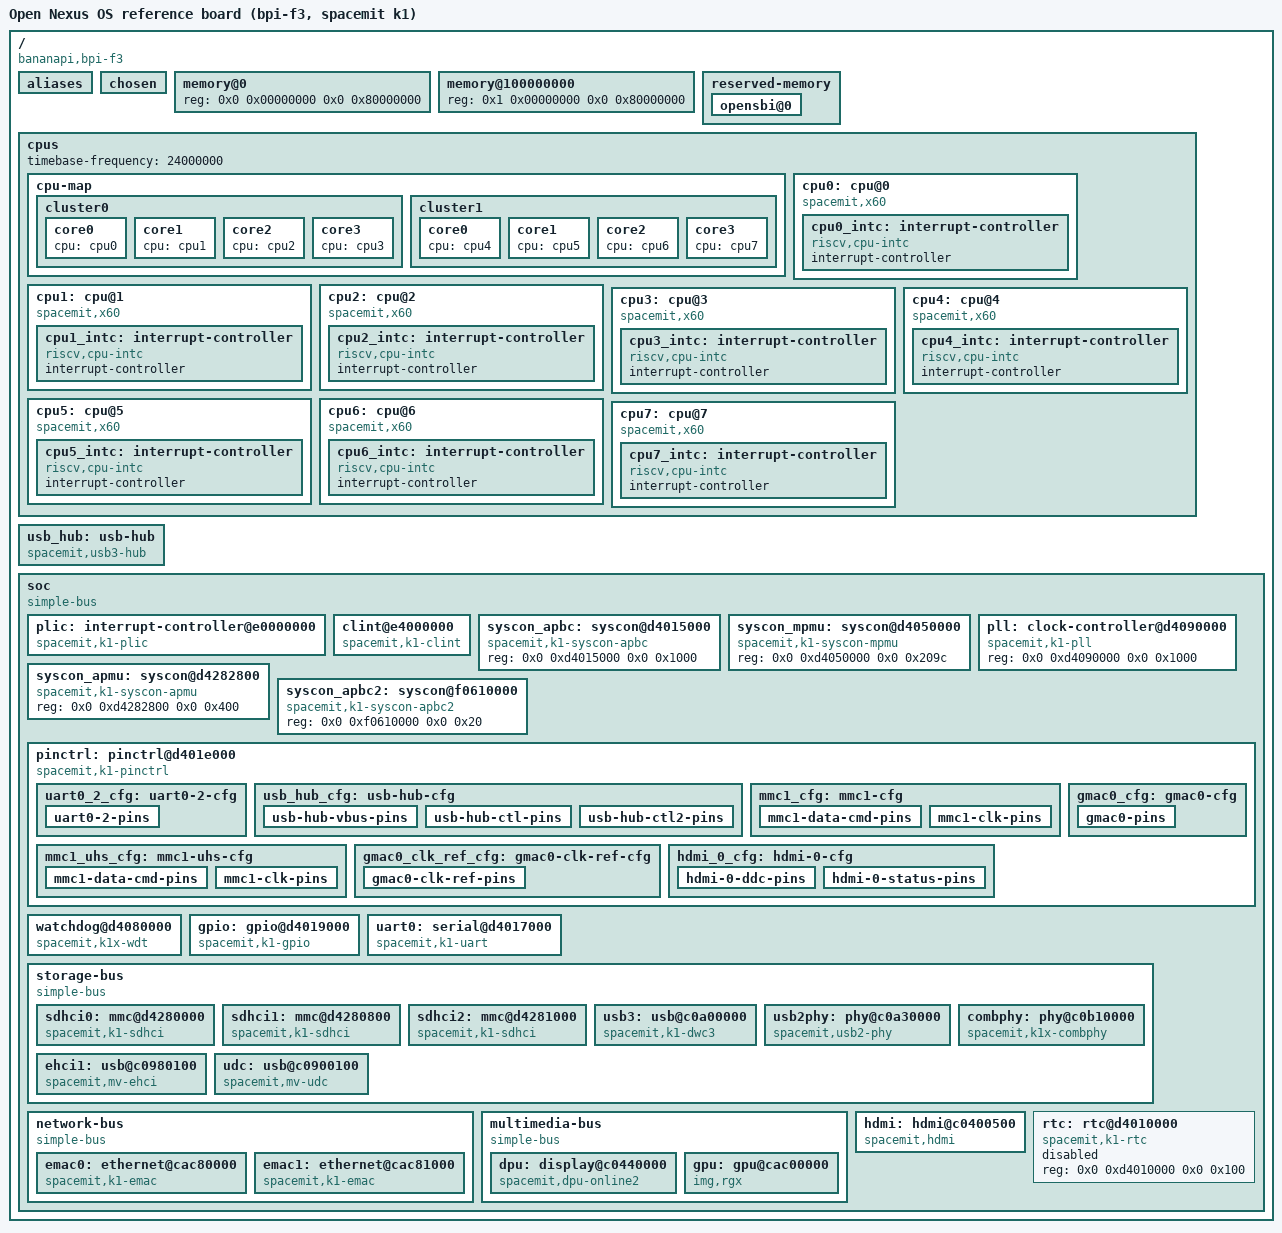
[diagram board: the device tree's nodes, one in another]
// SPDX-License-Identifier: Apache-2.0
// Copyright 2026 Open Nexus OS Contributors
//
// CONTEXT: the reference board's device tree as OUR boot chain hands it to the
// kernel (RFC-0098 C1). Written by hand from two sources and nothing else:
//   * the mainline SoC description (k1.dtsi, "GPL-2.0 OR MIT", used under MIT)
//     for the SoC-level nodes it has (cpus, plic, clint, uart, syscons, sdhci,
//     dwc3, emac, pinctrl);
//   * the facts measured on the desk board on 2026-09-22
//     (docs/board/measurements/2026-09-22-stock-system/README.md) for what
//     mainline does not describe yet (display controller, HDMI encoder, GPU,
//     EHCI, the OTG gadget, the power controller) — compatibles as the hardware
//     reports them, registers and interrupt lines as measured.
// It contains only the nodes Open Nexus OS consumes. Clock, reset, power-domain
// and pad bindings are expressed the standard way (TASK-0245B, RFC-0106): the
// providers carry their `#…-cells`, every consumer names its clocks/resets/
// domains/pads with the ids of config/board/include/dt-bindings (the mainline
// binding header, used under BSD-2-Clause; our own power-domain ids); `socd`
// resolves them through the `nexus-soc` tables, which hold register offsets
// with provenance and never an address.
//
// Compiled by scripts/build-board-dtb.sh (cpp for the headers, `dtc -p 512` for
// nxboot's /chosen headroom) into the FIT (ADR-0066) and, for the host tests of
// `nexus-fdt` and `nexus-soc`, into source/libs/nexus-fdt/tests/goldens/bpi-f3.dtb.

/dts-v1/;

#include <dt-bindings/clock/spacemit,k1-syscon.h>
#include <dt-bindings/power/spacemit,k1-pmu.h>

/* A pad-group entry: the pad number and its mux function (mainline convention). */
#define K1_PADCONF(pin, func) (((pin) << 16) | (func))

/ {
	compatible = "bananapi,bpi-f3", "spacemit,k1";
	model = "Open Nexus OS reference board (bpi-f3, spacemit k1)";
	#address-cells = <2>;
	#size-cells = <2>;

	aliases {
		serial0 = &uart0;
		mmc0 = &sdhci0;
		mmc1 = &sdhci1;
		mmc2 = &sdhci2;
		ethernet0 = &emac0;
		ethernet1 = &emac1;
	};

	chosen {
		stdout-path = "serial0:115200n8";
		// nexus,boot-profile / nexus,boot-slot / nexus,boot-record /
		// nexus,display-mode are written here by nxboot at boot (RFC-0098 C2).
		// The boot LED (TASK-0260B P3): the board's user LED, `sys-led`, GPIO bank 3
		// line 0 (= gpio 96, active high; measured on the stock system 2026-09-28,
		// docs/board/measurements/2026-09-28-dram-retention). nxboot brings the GPIO
		// block up and pulses it once; the kernel pulses its boot milestones on it —
		// the one channel a boot without a serial adapter leaves. The pad's mux
		// register and the value the stock system runs it with, so the loader sets it
		// before the first pulse: GPIO 96 is pad register 0x1e0 (pinctrl debugfs,
		// 2026-10-03: pin index 120, claimed by GPIO 96 `sys-led`, word 0xb041 — the
		// stock tree's GPIO mux value for that pad). Corrected 2026-10-03: this read
		// 0xd401e180 = 0x440, pinctrl-single's pin INDEX 96, an unclaimed pad.
		nexus,boot-led = <&gpio 3 0 0>;
		nexus,boot-led-pad = <0xd401e1e0 0xb041>;
	};

	// Measured: two banks, a 2 GiB hole between them (4 GiB board).
	memory@0 {
		device_type = "memory";
		reg = <0x0 0x00000000 0x0 0x80000000>;
	};

	memory@100000000 {
		device_type = "memory";
		reg = <0x1 0x00000000 0x0 0x80000000>;
	};

	reserved-memory {
		#address-cells = <2>;
		#size-cells = <2>;
		ranges;

		// OpenSBI (fw_dynamic, loaded at 0 by the SPL). Measured: the stock
		// system keeps 0..0x80000 reserved.
		opensbi@0 {
			reg = <0x0 0x00000000 0x0 0x00080000>;
			no-map;
		};
	};

	cpus {
		#address-cells = <1>;
		#size-cells = <0>;
		timebase-frequency = <24000000>;

		cpu-map {
			cluster0 {
				core0 { cpu = <&cpu0>; };
				core1 { cpu = <&cpu1>; };
				core2 { cpu = <&cpu2>; };
				core3 { cpu = <&cpu3>; };
			};
			cluster1 {
				core0 { cpu = <&cpu4>; };
				core1 { cpu = <&cpu5>; };
				core2 { cpu = <&cpu6>; };
				core3 { cpu = <&cpu7>; };
			};
		};

		cpu0: cpu@0 {
			compatible = "spacemit,x60", "riscv";
			device_type = "cpu";
			reg = <0>;
			riscv,isa-base = "rv64i";
			riscv,isa-extensions = "i", "m", "a", "f", "d", "c", "v", "zicbom", "zicboz", "zicntr", "zicond", "zicsr", "zifencei", "zihintpause", "zihpm", "zba", "zbb", "zbc", "zbs", "sscofpmf", "sstc", "svinval", "svnapot", "svpbmt";
			riscv,cbom-block-size = <64>;
			riscv,cboz-block-size = <64>;
			mmu-type = "riscv,sv39";
			status = "okay";
			cpu0_intc: interrupt-controller {
				compatible = "riscv,cpu-intc";
				interrupt-controller;
				#interrupt-cells = <1>;
			};
		};

		cpu1: cpu@1 {
			compatible = "spacemit,x60", "riscv";
			device_type = "cpu";
			reg = <1>;
			riscv,isa-base = "rv64i";
			riscv,isa-extensions = "i", "m", "a", "f", "d", "c", "v", "zicbom", "zicboz", "zicntr", "zicond", "zicsr", "zifencei", "zihintpause", "zihpm", "zba", "zbb", "zbc", "zbs", "sscofpmf", "sstc", "svinval", "svnapot", "svpbmt";
			riscv,cbom-block-size = <64>;
			riscv,cboz-block-size = <64>;
			mmu-type = "riscv,sv39";
			status = "okay";
			cpu1_intc: interrupt-controller {
				compatible = "riscv,cpu-intc";
				interrupt-controller;
				#interrupt-cells = <1>;
			};
		};

		cpu2: cpu@2 {
			compatible = "spacemit,x60", "riscv";
			device_type = "cpu";
			reg = <2>;
			riscv,isa-base = "rv64i";
			riscv,isa-extensions = "i", "m", "a", "f", "d", "c", "v", "zicbom", "zicboz", "zicntr", "zicond", "zicsr", "zifencei", "zihintpause", "zihpm", "zba", "zbb", "zbc", "zbs", "sscofpmf", "sstc", "svinval", "svnapot", "svpbmt";
			riscv,cbom-block-size = <64>;
			riscv,cboz-block-size = <64>;
			mmu-type = "riscv,sv39";
			status = "okay";
			cpu2_intc: interrupt-controller {
				compatible = "riscv,cpu-intc";
				interrupt-controller;
				#interrupt-cells = <1>;
			};
		};

		cpu3: cpu@3 {
			compatible = "spacemit,x60", "riscv";
			device_type = "cpu";
			reg = <3>;
			riscv,isa-base = "rv64i";
			riscv,isa-extensions = "i", "m", "a", "f", "d", "c", "v", "zicbom", "zicboz", "zicntr", "zicond", "zicsr", "zifencei", "zihintpause", "zihpm", "zba", "zbb", "zbc", "zbs", "sscofpmf", "sstc", "svinval", "svnapot", "svpbmt";
			riscv,cbom-block-size = <64>;
			riscv,cboz-block-size = <64>;
			mmu-type = "riscv,sv39";
			status = "okay";
			cpu3_intc: interrupt-controller {
				compatible = "riscv,cpu-intc";
				interrupt-controller;
				#interrupt-cells = <1>;
			};
		};

		cpu4: cpu@4 {
			compatible = "spacemit,x60", "riscv";
			device_type = "cpu";
			reg = <4>;
			riscv,isa-base = "rv64i";
			riscv,isa-extensions = "i", "m", "a", "f", "d", "c", "v", "zicbom", "zicboz", "zicntr", "zicond", "zicsr", "zifencei", "zihintpause", "zihpm", "zba", "zbb", "zbc", "zbs", "sscofpmf", "sstc", "svinval", "svnapot", "svpbmt";
			riscv,cbom-block-size = <64>;
			riscv,cboz-block-size = <64>;
			mmu-type = "riscv,sv39";
			status = "okay";
			cpu4_intc: interrupt-controller {
				compatible = "riscv,cpu-intc";
				interrupt-controller;
				#interrupt-cells = <1>;
			};
		};

		cpu5: cpu@5 {
			compatible = "spacemit,x60", "riscv";
			device_type = "cpu";
			reg = <5>;
			riscv,isa-base = "rv64i";
			riscv,isa-extensions = "i", "m", "a", "f", "d", "c", "v", "zicbom", "zicboz", "zicntr", "zicond", "zicsr", "zifencei", "zihintpause", "zihpm", "zba", "zbb", "zbc", "zbs", "sscofpmf", "sstc", "svinval", "svnapot", "svpbmt";
			riscv,cbom-block-size = <64>;
			riscv,cboz-block-size = <64>;
			mmu-type = "riscv,sv39";
			status = "okay";
			cpu5_intc: interrupt-controller {
				compatible = "riscv,cpu-intc";
				interrupt-controller;
				#interrupt-cells = <1>;
			};
		};

		cpu6: cpu@6 {
			compatible = "spacemit,x60", "riscv";
			device_type = "cpu";
			reg = <6>;
			riscv,isa-base = "rv64i";
			riscv,isa-extensions = "i", "m", "a", "f", "d", "c", "v", "zicbom", "zicboz", "zicntr", "zicond", "zicsr", "zifencei", "zihintpause", "zihpm", "zba", "zbb", "zbc", "zbs", "sscofpmf", "sstc", "svinval", "svnapot", "svpbmt";
			riscv,cbom-block-size = <64>;
			riscv,cboz-block-size = <64>;
			mmu-type = "riscv,sv39";
			status = "okay";
			cpu6_intc: interrupt-controller {
				compatible = "riscv,cpu-intc";
				interrupt-controller;
				#interrupt-cells = <1>;
			};
		};

		cpu7: cpu@7 {
			compatible = "spacemit,x60", "riscv";
			device_type = "cpu";
			reg = <7>;
			riscv,isa-base = "rv64i";
			riscv,isa-extensions = "i", "m", "a", "f", "d", "c", "v", "zicbom", "zicboz", "zicntr", "zicond", "zicsr", "zifencei", "zihintpause", "zihpm", "zba", "zbb", "zbc", "zbs", "sscofpmf", "sstc", "svinval", "svnapot", "svpbmt";
			riscv,cbom-block-size = <64>;
			riscv,cboz-block-size = <64>;
			mmu-type = "riscv,sv39";
			status = "okay";
			cpu7_intc: interrupt-controller {
				compatible = "riscv,cpu-intc";
				interrupt-controller;
				#interrupt-cells = <1>;
			};
		};
	};

	// The on-board USB hub (TASK-0328 U3, the stock `usb3hub@0` binding's shape; measured
	// 2026-10-04: GPIO 97 = VBUS, 123 and 124 = the hub's lines, all outputs driven high;
	// pads 97 mux 1 `0xa041`, 123 `0xa040`, 124 `0xd040`; the stock driver raises VBUS
	// 200 ms after the hub's lines). Bank 3 line n = GPIO 96 + n. socd drives the lines
	// (RFC-0106, amended): hub lines, the settle, then VBUS — before xhcid scans the port.
	// Not a bus device (no registers of its own), so it lives at the root like a regulator.
	usb_hub: usb-hub {
		compatible = "spacemit,usb3-hub";
		pinctrl-names = "default";
		pinctrl-0 = <&usb_hub_cfg>;
		hub-gpios = <&gpio 3 27 0>, <&gpio 3 28 0>;
		vbus-gpios = <&gpio 3 1 0>;
		vbus-delay-ms = <200>;
	};

	soc {
		compatible = "simple-bus";
		#address-cells = <2>;
		#size-cells = <2>;
		ranges;
		interrupt-parent = <&plic>;
		/* Measured R4 (docs/board/measurements/2026-09-22-stock-system): the
		 * masters do not snoop the CPU caches — the stock kernel bounces through
		 * swiotlb; the mainline K1 tree marks the bus the same way (RFC-0098 C4). */
		dma-noncoherent;

		plic: interrupt-controller@e0000000 {
			compatible = "spacemit,k1-plic", "sifive,plic-1.0.0", "riscv,plic0";
			reg = <0x0 0xe0000000 0x0 0x4000000>;
			interrupt-controller;
			#interrupt-cells = <1>;
			#address-cells = <0>;
			riscv,ndev = <159>;
			interrupts-extended = <&cpu0_intc 11>, <&cpu0_intc 9>,
					      <&cpu1_intc 11>, <&cpu1_intc 9>,
					      <&cpu2_intc 11>, <&cpu2_intc 9>,
					      <&cpu3_intc 11>, <&cpu3_intc 9>,
					      <&cpu4_intc 11>, <&cpu4_intc 9>,
					      <&cpu5_intc 11>, <&cpu5_intc 9>,
					      <&cpu6_intc 11>, <&cpu6_intc 9>,
					      <&cpu7_intc 11>, <&cpu7_intc 9>;
		};

		// M-mode only: S-mode never maps it. The SPL hands this very tree to OpenSBI,
		// whose ACLINT drivers serve exactly the harts named here (IPI: MSIP 3, timer:
		// MTIP 7). Without the list its timer serves no hart and it stops before the
		// next stage (OpenSBI v1.3: fdt_parse_aclint_node, aclint_mtimer_warm_init →
		// "timer init failed"; TASK-0260B, the first board attempt).
		clint@e4000000 {
			compatible = "spacemit,k1-clint", "sifive,clint0";
			reg = <0x0 0xe4000000 0x0 0x10000>;
			interrupts-extended = <&cpu0_intc 3>, <&cpu0_intc 7>,
					      <&cpu1_intc 3>, <&cpu1_intc 7>,
					      <&cpu2_intc 3>, <&cpu2_intc 7>,
					      <&cpu3_intc 3>, <&cpu3_intc 7>,
					      <&cpu4_intc 3>, <&cpu4_intc 7>,
					      <&cpu5_intc 3>, <&cpu5_intc 7>,
					      <&cpu6_intc 3>, <&cpu6_intc 7>,
					      <&cpu7_intc 3>, <&cpu7_intc 7>;
		};

		// The clock/reset/power syscon windows (mainline names); the providers
		// `socd` owns (RFC-0106). Ids per dt-bindings/clock/spacemit,k1-syscon.h.
		syscon_apbc: syscon@d4015000 {
			compatible = "spacemit,k1-syscon-apbc";
			reg = <0x0 0xd4015000 0x0 0x1000>;
			#clock-cells = <1>;
			#reset-cells = <1>;
		};
		syscon_mpmu: syscon@d4050000 {
			compatible = "spacemit,k1-syscon-mpmu";
			reg = <0x0 0xd4050000 0x0 0x209c>;
			#clock-cells = <1>;
			// A consumer's glue words in the MPMU (`<&syscon_mpmu offset mask value>`,
			// TASK-0328 U3: the USB PHYs' clock control word at 0x14).
			#nexus,glue-cells = <3>;
			#reset-cells = <1>;
			#power-domain-cells = <1>;
		};
		pll: clock-controller@d4090000 {
			compatible = "spacemit,k1-pll";
			reg = <0x0 0xd4090000 0x0 0x1000>;
			#clock-cells = <1>;
		};
		syscon_apmu: syscon@d4282800 {
			compatible = "spacemit,k1-syscon-apmu";
			reg = <0x0 0xd4282800 0x0 0x400>;
			#clock-cells = <1>;
			#reset-cells = <1>;
			// A consumer's glue words (`nexus,glue-words = <&syscon_apmu offset mask value>`):
			// a vendor driver's one-word controller glue, its `mask` bits set by socd, the
			// rest (status bits) left alone (TASK-0328 U3: the USB host's word at 0x3c8).
			#nexus,glue-cells = <3>;
			#power-domain-cells = <1>;
		};
		syscon_apbc2: syscon@f0610000 {
			compatible = "spacemit,k1-syscon-apbc2";
			reg = <0x0 0xf0610000 0x0 0x20>;
			#reset-cells = <1>;
		};

		pinctrl: pinctrl@d401e000 {
			compatible = "spacemit,k1-pinctrl";
			reg = <0x0 0xd401e000 0x0 0x1000>;
			clocks = <&syscon_apbc CLK_AIB>, <&syscon_apbc CLK_AIB_BUS>;
			clock-names = "func", "bus";
			resets = <&syscon_apbc RESET_AIB>;

			// Pad groups (mainline k1-pinctrl.dtsi, GPL-2.0 OR MIT, used under
			// MIT): only the ones our consumers reference.
			uart0_2_cfg: uart0-2-cfg {
				uart0-2-pins {
					pinmux = <K1_PADCONF(68, 2)>,	/* uart0_txd */
						 <K1_PADCONF(69, 2)>;	/* uart0_rxd */
					bias-pull-up = <0>;
					drive-strength = <32>;
				};
			};

			// The on-board USB hub's lines as GPIOs (TASK-0328 U3; the owned fields of
			// the stock words: 97 `0xa041` = function 1 pull-down, 123 `0xa040` = function 0
			// pull-down, 124 `0xd040` = function 0 pull-up).
			usb_hub_cfg: usb-hub-cfg {
				usb-hub-vbus-pins {
					pinmux = <K1_PADCONF(97, 1)>;	/* gpio 97: VBUS */
					bias-pull-down = <0>;
				};
				usb-hub-ctl-pins {
					pinmux = <K1_PADCONF(123, 0)>;	/* gpio 123 */
					bias-pull-down = <0>;
				};
				usb-hub-ctl2-pins {
					pinmux = <K1_PADCONF(124, 0)>;	/* gpio 124 */
					bias-pull-up = <0>;
				};
			};

			mmc1_cfg: mmc1-cfg {
				mmc1-data-cmd-pins {
					pinmux = <K1_PADCONF(104, 0)>,	/* mmc1_d3 */
						 <K1_PADCONF(105, 0)>,	/* mmc1_d2 */
						 <K1_PADCONF(106, 0)>,	/* mmc1_d1 */
						 <K1_PADCONF(107, 0)>,	/* mmc1_d0 */
						 <K1_PADCONF(108, 0)>;	/* mmc1_cmd */
					bias-pull-up = <1>;
					drive-strength = <19>;
					power-source = <3300>;
				};
				mmc1-clk-pins {
					pinmux = <K1_PADCONF(109, 0)>;	/* mmc1_clk */
					bias-pull-down = <1>;
					drive-strength = <19>;
					power-source = <3300>;
				};
			};

			mmc1_uhs_cfg: mmc1-uhs-cfg {
				mmc1-data-cmd-pins {
					pinmux = <K1_PADCONF(104, 0)>,
						 <K1_PADCONF(105, 0)>,
						 <K1_PADCONF(106, 0)>,
						 <K1_PADCONF(107, 0)>,
						 <K1_PADCONF(108, 0)>;
					bias-pull-up = <1>;
					drive-strength = <42>;
					power-source = <1800>;
				};
				mmc1-clk-pins {
					pinmux = <K1_PADCONF(109, 0)>;
					bias-pull-down = <1>;
					drive-strength = <42>;
					power-source = <1800>;
				};
			};

			gmac0_cfg: gmac0-cfg {
				gmac0-pins {
					pinmux = <K1_PADCONF(0, 1)>,	/* gmac0_rxdv */
						 <K1_PADCONF(1, 1)>,	/* gmac0_rx_d0 */
						 <K1_PADCONF(2, 1)>,	/* gmac0_rx_d1 */
						 <K1_PADCONF(3, 1)>,	/* gmac0_rx_clk */
						 <K1_PADCONF(4, 1)>,	/* gmac0_rx_d2 */
						 <K1_PADCONF(5, 1)>,	/* gmac0_rx_d3 */
						 <K1_PADCONF(6, 1)>,	/* gmac0_tx_d0 */
						 <K1_PADCONF(7, 1)>,	/* gmac0_tx_d1 */
						 <K1_PADCONF(8, 1)>,	/* gmac0_tx */
						 <K1_PADCONF(9, 1)>,	/* gmac0_tx_d2 */
						 <K1_PADCONF(10, 1)>,	/* gmac0_tx_d3 */
						 <K1_PADCONF(11, 1)>,	/* gmac0_tx_en */
						 <K1_PADCONF(12, 1)>;	/* gmac0_mdc */
					bias-pull-up = <0>;
					drive-strength = <21>;
				};
			};
			gmac0_clk_ref_cfg: gmac0-clk-ref-cfg {
				gmac0-clk-ref-pins {
					pinmux = <K1_PADCONF(45, 1)>;	/* gmac0_clk_ref */
					bias-pull-up = <0>;
					drive-strength = <21>;
				};
			};

			// The HDMI encoder's four pads (the stock system's `hdmi_0_grp`, read live
			// 2026-10-03, docs/board/measurements/2026-10-03-first-light/: function 1;
			// words 0xd041 on the first two, pulled up — the DDC pair — and 0xb041 on the
			// other two, pulled down). Without them the encoder sees no hot-plug.
			hdmi_0_cfg: hdmi-0-cfg {
				hdmi-0-ddc-pins {
					pinmux = <K1_PADCONF(86, 1)>,
						 <K1_PADCONF(87, 1)>;
					bias-pull-up;
				};
				hdmi-0-status-pins {
					pinmux = <K1_PADCONF(88, 1)>,
						 <K1_PADCONF(89, 1)>;
					bias-pull-down;
				};
			};
		};

		// The SoC watchdog (the vendor U-Boot's tree, `k1-x.dtsi`: the register window and
		// the reset-enable word at 0xd4051020). Named so nxboot can STOP it: the vendor
		// chain's U-Boot starts, feeds and stops it before Linux; ours never runs U-Boot
		// (TASK-0260B P3 — the kernel died mid-line, seconds in, until this). Nothing
		// else consumes it; its clock is the one it is already running on.
		watchdog@d4080000 {
			compatible = "spacemit,k1x-wdt";
			reg = <0x0 0xd4080000 0x0 0x1000>,
			      <0x0 0xd4051020 0x0 0x4>;
		};

		// The GPIO block (mainline shape; reg as the stock system maps it — the driver's
		// bank 3 lies at +0x100). Consumed for the boot LED only (TASK-0260B P3).
		gpio: gpio@d4019000 {
			compatible = "spacemit,k1-gpio";
			reg = <0x0 0xd4019000 0x0 0x800>;
			clocks = <&syscon_apbc CLK_GPIO>, <&syscon_apbc CLK_GPIO_BUS>;
			clock-names = "core", "bus";
			gpio-controller;
			#gpio-cells = <3>;
		};

		// The debug console: 16550-class registers at a 4-byte stride. `spacemit,pxa-uart`
		// is the name the pinned OpenSBI's console driver matches (its binary's match
		// strings, TASK-0260B), so the firmware prints on it too.
		uart0: serial@d4017000 {
			compatible = "spacemit,k1-uart", "spacemit,pxa-uart", "intel,xscale-uart";
			reg = <0x0 0xd4017000 0x0 0x100>;
			reg-shift = <2>;
			reg-io-width = <4>;
			interrupts = <42>;
			clocks = <&syscon_apbc CLK_UART0>, <&syscon_apbc CLK_UART0_BUS>;
			clock-names = "core", "bus";
			resets = <&syscon_apbc RESET_UART0>;
			pinctrl-names = "default";
			pinctrl-0 = <&uart0_2_cfg>;
			status = "okay";
		};

		// DMA reach (RFC-0098 C4), measured 2026-09-24 (docs/board/measurements/
		// 2026-09-24-emmc-sdhci): the stock tree's `dram_range@0`, mainline's `storage-bus`.
		// The storage masters reach ONLY the first 2 GiB, identity; bank 1 is out of reach.
		storage-bus {
			compatible = "simple-bus";
			ranges;
			#address-cells = <2>;
			#size-cells = <2>;
			dma-ranges = <0x0 0x00000000 0x0 0x00000000 0x0 0x80000000>;

			// What each SD host may carry, the standard way (`no-mmc`/`no-sd`/`no-sdio`), as the
			// stock system's live tree marks them (measured 2026-09-26, docs/board/measurements/
			// 2026-09-24-emmc-sdhci/live-tree-sdh.txt): the loader's boot-disk rule and the block
			// owner treat only a host without `no-mmc` as one that may hold an eMMC.

			// The microSD slot.
			sdhci0: mmc@d4280000 {
				compatible = "spacemit,k1-sdhci";
				reg = <0x0 0xd4280000 0x0 0x200>;
				interrupts = <99>;
				clocks = <&syscon_apmu CLK_SDH_AXI>, <&syscon_apmu CLK_SDH0>;
				clock-names = "core", "io";
				resets = <&syscon_apmu RESET_SDH_AXI>, <&syscon_apmu RESET_SDH0>;
				reset-names = "axi", "sdh";
				power-domains = <&syscon_apmu K1_PD_BUS>;
				pinctrl-names = "default", "uhs";
				pinctrl-0 = <&mmc1_cfg>;
				pinctrl-1 = <&mmc1_uhs_cfg>;
				bus-width = <4>;
				no-mmc;
				no-sdio;
				status = "okay";
			};

			// The SDIO WiFi function.
			sdhci1: mmc@d4280800 {
				compatible = "spacemit,k1-sdhci";
				reg = <0x0 0xd4280800 0x0 0x200>;
				interrupts = <100>;
				clocks = <&syscon_apmu CLK_SDH_AXI>, <&syscon_apmu CLK_SDH1>;
				clock-names = "core", "io";
				resets = <&syscon_apmu RESET_SDH_AXI>, <&syscon_apmu RESET_SDH1>;
				reset-names = "axi", "sdh";
				power-domains = <&syscon_apmu K1_PD_BUS>;
				bus-width = <4>;
				non-removable;
				no-mmc;
				no-sd;
				status = "okay";
			};

			// The system disk (eMMC, 8-bit, HS400 with enhanced strobe at 1.8 V).
			sdhci2: mmc@d4281000 {
				compatible = "spacemit,k1-sdhci";
				reg = <0x0 0xd4281000 0x0 0x200>;
				interrupts = <101>;
				clocks = <&syscon_apmu CLK_SDH_AXI>, <&syscon_apmu CLK_SDH2>;
				clock-names = "core", "io";
				resets = <&syscon_apmu RESET_SDH_AXI>, <&syscon_apmu RESET_SDH2>;
				reset-names = "axi", "sdh";
				power-domains = <&syscon_apmu K1_PD_BUS>;
				bus-width = <8>;
				non-removable;
				no-sd;
				no-sdio;
				mmc-hs400-1_8v;
				mmc-hs400-enhanced-strobe;
				status = "okay";
			};

			// USB: the DWC3 host (xHCI), the EHCI host, the OTG gadget.
			// TASK-0328 U3 (RFC-0099 §6): the host's glue as measured on the stock system
			// (docs/board/measurements/2026-10-04-usb-topology/): the APMU glue word at
			// 0x3c8 (the stock glue node's own register, `0xd4282bc8 = 0x0b008000`), the
			// USB 2.0 PHY it drives the USB-A ports through (the SuperSpeed lane is left
			// alone in v1), and the on-board hub on its USB 2.0 root port (`usb_hub`).
			usb3: usb@c0a00000 {
				compatible = "spacemit,k1-dwc3", "snps,dwc3";
				reg = <0x0 0xc0a00000 0x0 0x10000>;
				interrupts = <125>;
				// The USB AXI clock and reset too (bits 1 and 0 of the APMU USB word): the
				// stock system runs the word as 0x0f33; cycle 6 of U3 had 0xf00 and an xHCI
				// that never left its reset.
				clocks = <&syscon_apmu CLK_USB30>, <&syscon_apmu CLK_USB_AXI>;
				clock-names = "usbdrd30", "axi";
				resets = <&syscon_apmu RESET_USB30_AHB>, <&syscon_apmu RESET_USB30_VCC>,
					 <&syscon_apmu RESET_USB30_PHY>, <&syscon_apmu RESET_USB_AXI>;
				reset-names = "ahb", "vcc", "phy", "axi";
				power-domains = <&syscon_apmu K1_PD_BUS>;
				// The stock word is 0x0b008000; its bits 24..25 are status (cycle 1,
				// 2026-10-05: written, they read back clear — docs/board/measurements/
				// 2026-10-05-usb-cycle1/), so only bit 15 is the glue.
				nexus,glue-words = <&syscon_apmu 0x3c8 0x00008000 0x00008000>;
				usb-phy = <&usb2phy>;
				dr_mode = "host";
				status = "okay";
			};

			// The USB 2.0 PHY of the DWC3 host (stock `usb2phy@0xc0a30000`): xhcid reads its
			// tuning words and compares them with the stock system's (U3's first cycle).
			usb2phy: phy@c0a30000 {
				compatible = "spacemit,usb2-phy";
				reg = <0x0 0xc0a30000 0x0 0x200>;
				clocks = <&syscon_apmu CLK_USB30>;
				clock-names = "usbdrd30";
				// The MPMU word at 0x14 as the stock system runs it (cycle 8 of U3 measured
				// ours as 0x1fbd0600 with both USB PHYs dead; the stock desktop 0x007d0018):
				// the PHYs' clock control by the look of it — written whole, each bit
				// read back, through socd before xhcid touches the PHY.
				nexus,glue-words = <&syscon_mpmu 0x14 0xffffffff 0x007d0018>;
				#phy-cells = <0>;
				status = "okay";
			};

			// The SuperSpeed (combo) PHY of the host's USB 3.0 root port (stock
			// `phy@c0b10000`, its `puphy` block; the stock `phy_sel` block is the APMU's
			// own words). The xHCI's reset waits on this PHY's PIPE clock (cycles 4-9 of
			// U3: HCRST never completed with the block reading all zeros), so it is
			// brought up, not only measured: the PHY shares PCIe port A's global reset
			// (bit 8 of the APMU's 0x3cc, SET = held — our loader leaves it set, the
			// stock word 0x480 runs it clear) and the port's "hold PHY reset" bit (bit 30
			// of the same word, the vendor PHY driver clears it before calibrating); the
			// lane select at 0x110 (stock 0x8) puts the lane on USB. socd writes them
			// before xhcid runs the PHY's PLL sequence (`ss_phy.rs`).
			combphy: phy@c0b10000 {
				compatible = "spacemit,k1x-combphy";
				reg = <0x0 0xc0b10000 0x0 0x800>;
				resets = <&syscon_apmu RESET_PCIE0_GLOBAL>;
				reset-names = "phy";
				nexus,glue-words = <&syscon_apmu 0x3cc 0x40000000 0x00000000>,
						   <&syscon_apmu 0x110 0x00000008 0x00000008>;
				#phy-cells = <1>;
				status = "okay";
			};

			ehci1: usb@c0980100 {
				compatible = "spacemit,mv-ehci";
				reg = <0x0 0xc0980100 0x0 0x4000>;
				interrupts = <118>;
				clocks = <&syscon_apmu CLK_USB_P1>;
				resets = <&syscon_apmu RESET_USBP1_AXI>;
				power-domains = <&syscon_apmu K1_PD_BUS>;
				status = "okay";
			};

			udc: usb@c0900100 {
				compatible = "spacemit,mv-udc";
				reg = <0x0 0xc0900100 0x0 0x4000>;
				interrupts = <105>;
				clocks = <&syscon_apmu CLK_USB_AXI>;
				resets = <&syscon_apmu RESET_USB_AXI>;
				power-domains = <&syscon_apmu K1_PD_BUS>;
				status = "okay";
			};
		};

		// The GMACs (stock `dram_range@5`, mainline `network-bus`): the first 2 GiB identity, and
		// bus 0x8000_0000.. reaches CPU 0x1_0000_0000.. (2 GiB) — a translated window.
		network-bus {
			compatible = "simple-bus";
			ranges;
			#address-cells = <2>;
			#size-cells = <2>;
			dma-ranges = <0x0 0x00000000 0x0 0x00000000 0x0 0x80000000>,
				     <0x0 0x80000000 0x1 0x00000000 0x0 0x80000000>;

			emac0: ethernet@cac80000 {
				compatible = "spacemit,k1-emac";
				reg = <0x0 0xcac80000 0x0 0x420>;
				interrupts = <131>;
				clocks = <&syscon_apmu CLK_EMAC0_BUS>, <&syscon_apmu CLK_EMAC0_PTP>;
				clock-names = "bus", "ptp";
				resets = <&syscon_apmu RESET_EMAC0>;
				power-domains = <&syscon_apmu K1_PD_BUS>;
				pinctrl-names = "default";
				pinctrl-0 = <&gmac0_cfg>, <&gmac0_clk_ref_cfg>;
				status = "okay";
			};

			emac1: ethernet@cac81000 {
				compatible = "spacemit,k1-emac";
				reg = <0x0 0xcac81000 0x0 0x420>;
				interrupts = <133>;
				clocks = <&syscon_apmu CLK_EMAC1_BUS>, <&syscon_apmu CLK_EMAC1_PTP>;
				clock-names = "bus", "ptp";
				resets = <&syscon_apmu RESET_EMAC1>;
				power-domains = <&syscon_apmu K1_PD_BUS>;
				status = "okay";
			};
		};

		// The display controller and the GPU (stock `dram_range@1`; mainline has the bus, not yet
		// these nodes): the first 2 GiB identity, and bus 0x8000_0000.. reaches CPU
		// 0x1_0000_0000.. (14 GiB).
		multimedia-bus {
			compatible = "simple-bus";
			ranges;
			#address-cells = <2>;
			#size-cells = <2>;
			dma-ranges = <0x0 0x00000000 0x0 0x00000000 0x0 0x80000000>,
				     <0x0 0x80000000 0x1 0x00000000 0x3 0x80000000>;

			// Display pipeline (measured; not in mainline yet).
			dpu: display@c0440000 {
				compatible = "spacemit,dpu-online2";
				reg = <0x0 0xc0440000 0x0 0x2a000>;
				interrupts = <139>, <138>;
				interrupt-names = "online", "offline";
				// The HDMI pipeline runs on hmclk alone — the five DSI clocks are off
				// with the picture on — at the rate measured running (491.52 MHz,
				// docs/board/measurements/2026-09-29-display-regs/).
				clocks = <&syscon_apmu CLK_HDMI>;
				clock-names = "hmclk";
				assigned-clocks = <&syscon_apmu CLK_HDMI>;
				assigned-clock-rates = <491520000>;
				resets = <&syscon_apmu RESET_HDMI>;
				reset-names = "hdmi_reset";
				power-domains = <&syscon_apmu K1_PD_HDMI>;
				status = "okay";
			};

			gpu: gpu@cac00000 {
				compatible = "img,rgx";
				reg = <0x0 0xcac00000 0x0 0x80000>;
				interrupts = <75>;
				clocks = <&syscon_apmu CLK_GPU>;
				clock-names = "gpu";
				resets = <&syscon_apmu RESET_GPU>;
				power-domains = <&syscon_apmu K1_PD_GPU>;
				status = "okay";
			};
		};

		hdmi: hdmi@c0400500 {
			compatible = "spacemit,hdmi";
			reg = <0x0 0xc0400500 0x0 0x200>;
			interrupts = <136>;
			clocks = <&syscon_apmu CLK_HDMI>;
			clock-names = "hmclk";
			assigned-clocks = <&syscon_apmu CLK_HDMI>;
			assigned-clock-rates = <491520000>;
			resets = <&syscon_apmu RESET_HDMI>;
			reset-names = "hdmi_reset";
			power-domains = <&syscon_apmu K1_PD_HDMI>;
			pinctrl-names = "default";
			pinctrl-0 = <&hdmi_0_cfg>;
			status = "okay";
		};

		rtc: rtc@d4010000 {
			compatible = "spacemit,k1-rtc";
			reg = <0x0 0xd4010000 0x0 0x100>;
			status = "disabled";
		};
	};
};
